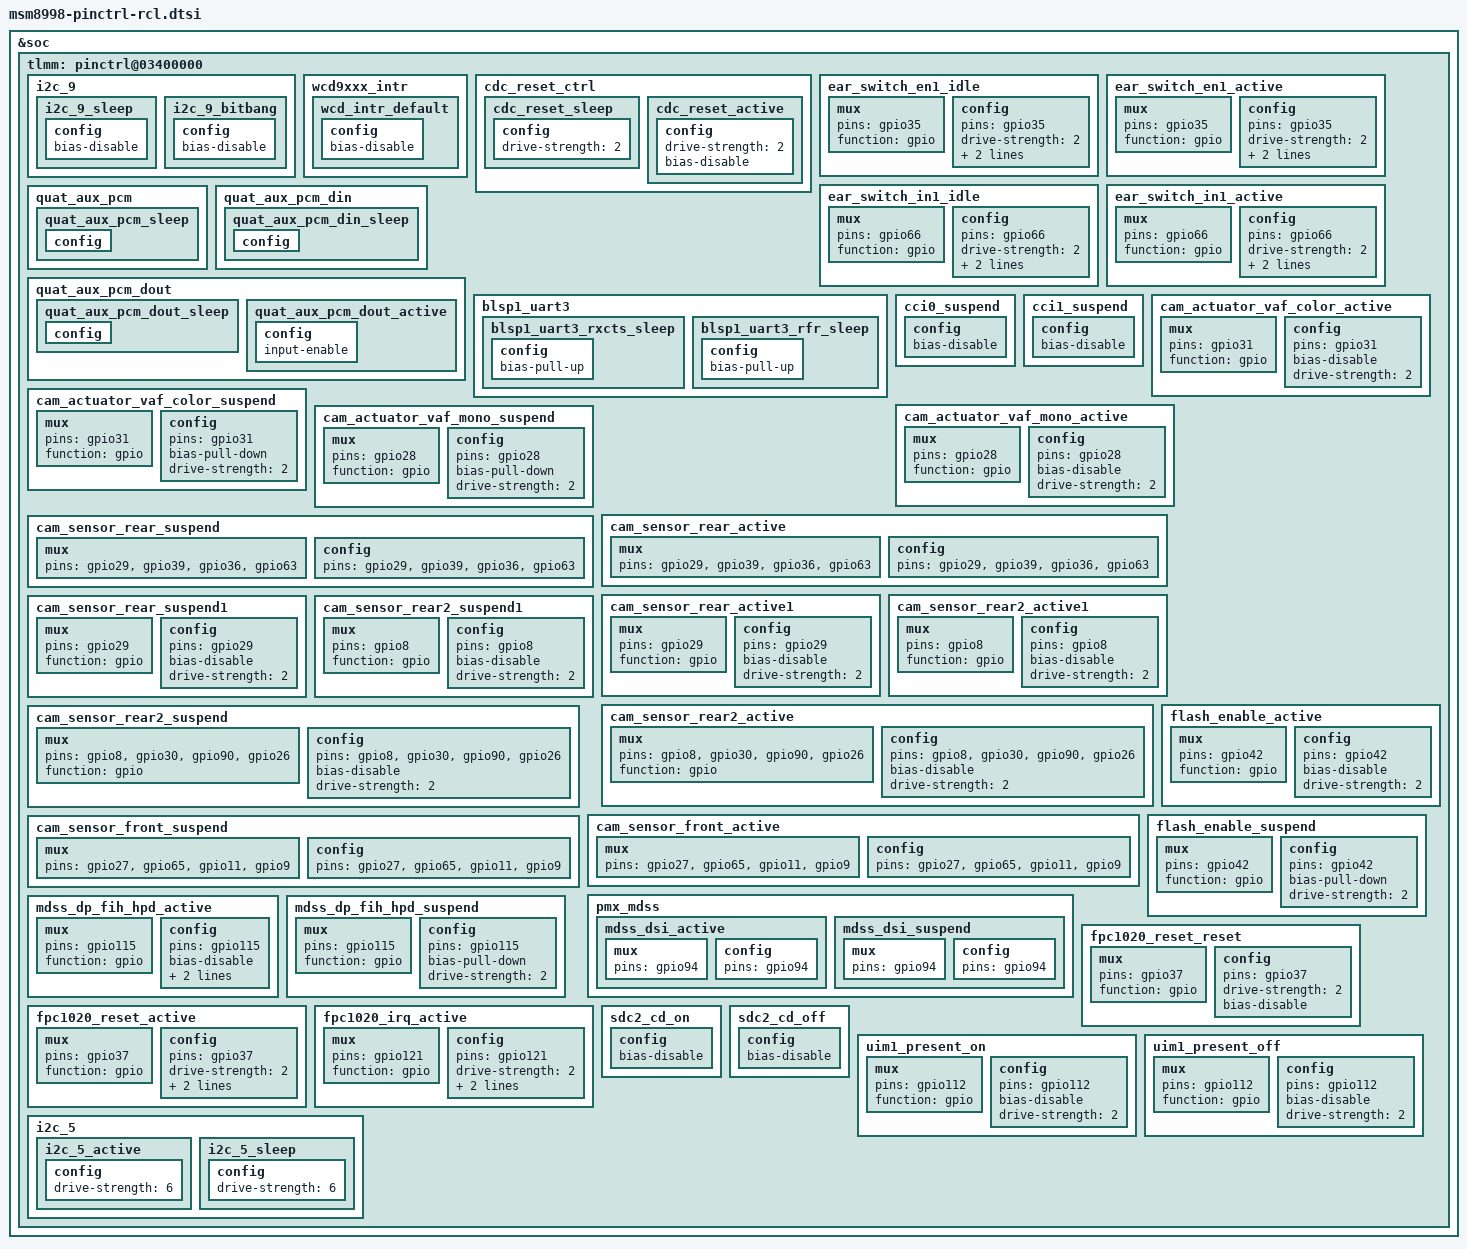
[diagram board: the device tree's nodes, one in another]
/* Copyright (c) 2015-2018, The Linux Foundation. All rights reserved.
 *
 * This program is free software; you can redistribute it and/or modify
 * it under the terms of the GNU General Public License version 2 and
 * only version 2 as published by the Free Software Foundation.
 *
 * This program is distributed in the hope that it will be useful,
 * but WITHOUT ANY WARRANTY; without even the implied warranty of
 * MERCHANTABILITY or FITNESS FOR A PARTICULAR PURPOSE.  See the
 * GNU General Public License for more details.
 */

&soc {
	tlmm: pinctrl@03400000 {
		/* Audio */
		i2c_9 {
			i2c_9_sleep: i2c_9_sleep {
				config {
					/delete-property/ bias-pull-up;
					bias-disable;
				};
			};

			i2c_9_bitbang: i2c_9_bitbang {
				config {
					/delete-property/ bias-pull-up;
					bias-disable;
				};
			};
		};

		wcd9xxx_intr {
			wcd_intr_default: wcd_intr_default {
				config {
					/delete-property/ bias-pull-down;
					bias-disable;
				};
			};
		};

		cdc_reset_ctrl {
			cdc_reset_sleep: cdc_reset_sleep {
				config {
					drive-strength = <2>;
				};
			};

			cdc_reset_active: cdc_reset_active {
				config {
					drive-strength = <2>;
					/delete-property/ bias-pull-down;
					bias-disable;
				};
			};
		};

		ear_switch_en1_idle: ear_switch_en1_idle {
			mux {
				pins = "gpio35";
				function = "gpio";
			};

			config {
				pins = "gpio35";
				drive-strength = <2>;
				bias-pull-down;
				output-low;
			};
		};

		ear_switch_en1_active: ear_switch_en1_active {
			mux {
				pins = "gpio35";
				function = "gpio";
			};

			config {
				pins = "gpio35";
				drive-strength = <2>;
				bias-disable;
				output-high;
			};
		};

		ear_switch_in1_idle: ear_switch_in1_idle {
			mux {
				pins = "gpio66";
				function = "gpio";
			};

			config {
				pins = "gpio66";
				drive-strength = <2>;
				bias-pull-down;
				output-low;
			};
		};

		ear_switch_in1_active: ear_switch_in1_active {
			mux {
				pins = "gpio66";
				function = "gpio";
			};

			config {
				pins = "gpio66";
				drive-strength = <2>;
				bias-disable;
				output-high;
			};
		};

		quat_aux_pcm {
			quat_aux_pcm_sleep: quat_aux_pcm_sleep {
				config {
					/delete-property/ input-enable;
				};
			};
		};

		quat_aux_pcm_din {
			quat_aux_pcm_din_sleep: quat_aux_pcm_din_sleep {
				config {
					/delete-property/ input-enable;
				};
			};
		};

		quat_aux_pcm_dout {
			quat_aux_pcm_dout_sleep: quat_aux_pcm_dout_sleep {
				config {
					/delete-property/ input-enable;
				};
			};

			quat_aux_pcm_dout_active: quat_aux_pcm_dout_active {
				config {
					input-enable;
				};
			};
		};

		/* Bluetooth */
		blsp1_uart3: blsp1_uart3 {
			blsp1_uart3_rxcts_sleep: blsp1_uart3_rxcts_sleep {
				config {
					/delete-property/ bias-no-pull;
					bias-pull-up;
				};
			};

			blsp1_uart3_rfr_sleep: blsp1_uart3_rfr_sleep {
				config {
					/delete-property/ bias-no-pull;
					bias-pull-up;
				};
			};
		};

		/* Camera */
		cci0_suspend: cci0_suspend {
			config {
				/delete-property/ bias-pull-down;
				bias-disable; /* No PULL */
			};
		};

		cci1_suspend: cci1_suspend {
			config {
				/delete-property/ bias-pull-down;
				bias-disable; /* No PULL */
			};
		};

		cam_actuator_vaf_color_active: cam_actuator_vaf_color_active {
			/* ACTUATOR POWER */
			mux {
				pins = "gpio31";
				function = "gpio";
			};

			config {
				pins = "gpio31";
				bias-disable; /* No PULL */
				drive-strength = <2>; /* 2 MA */
			};
		};

		cam_actuator_vaf_color_suspend: cam_actuator_vaf_color_suspend {
			/* ACTUATOR POWER */
			mux {
				pins = "gpio31";
				function = "gpio";
			};

			config {
				pins = "gpio31";
				bias-pull-down; /* PULL DOWN */
				drive-strength = <2>; /* 2 MA */
			};
		};

		cam_actuator_vaf_mono_active: cam_actuator_vaf_mono_active {
			/* ACTUATOR POWER */
			mux {
				pins = "gpio28";
				function = "gpio";
			};

			config {
				pins = "gpio28";
				bias-disable; /* No PULL */
				drive-strength = <2>; /* 2 MA */
			};
		};

		cam_actuator_vaf_mono_suspend: cam_actuator_vaf_mono_suspend {
			/* ACTUATOR POWER */
			mux {
				pins = "gpio28";
				function = "gpio";
			};

			config {
				pins = "gpio28";
				bias-pull-down; /* PULL DOWN */
				drive-strength = <2>; /* 2 MA */
			};
		};

		cam_sensor_rear_active: cam_sensor_rear_active {
			/* RESET, DVDD_EN, AVDD_EN, IOVDD_EN */
			mux {
				pins = "gpio29", "gpio39", "gpio36", "gpio63";
			};

			config {
				pins = "gpio29", "gpio39", "gpio36", "gpio63";
			};
		};

		cam_sensor_rear_suspend: cam_sensor_rear_suspend {
			/* RESET, DVDD_EN, AVDD_EN, IOVDD_EN */
			mux {
				pins = "gpio29", "gpio39", "gpio36", "gpio63";
			};

			config {
				pins = "gpio29", "gpio39", "gpio36", "gpio63";
			};
		};

		cam_sensor_rear_active1: cam_sensor_rear_active1 {
			mux {
				pins = "gpio29";
				function = "gpio";
			};

			config {
				pins = "gpio29";
				bias-disable; /* No PULL */
				drive-strength = <2>; /* 2 MA */
			};
		};

		cam_sensor_rear2_active1: cam_sensor_rear2_active1 {
			mux {
				pins = "gpio8";
				function = "gpio";
			};

			config {
				pins = "gpio8";
				bias-disable; /* No PULL */
				drive-strength = <2>; /* 2 MA */
			};
		};

		cam_sensor_rear_suspend1: cam_sensor_rear_suspend1 {
			mux {
				pins = "gpio29";
				function = "gpio";
			};

			config {
				pins = "gpio29";
				bias-disable; /* No PULL */
				drive-strength = <2>; /* 2 MA */
			};
		};

		cam_sensor_rear2_suspend1: cam_sensor_rear2_suspend1 {
			mux {
				pins = "gpio8";
				function = "gpio";
			};

			config {
				pins = "gpio8";
				bias-disable; /* No PULL */
				drive-strength = <2>; /* 2 MA */
			};
		};

		cam_sensor_rear2_active: cam_sensor_rear2_active {
			/* RESET, AVDD_EN, DVDD_EN, IOVDD_EN */
			mux {
				pins = "gpio8", "gpio30", "gpio90", "gpio26";
				function = "gpio";
			};

			config {
				pins = "gpio8", "gpio30", "gpio90", "gpio26";
				bias-disable; /* No PULL */
				drive-strength = <2>; /* 2 MA */
			};
		};

		cam_sensor_rear2_suspend: cam_sensor_rear2_suspend {
			/* RESET, AVDD_EN, DVDD_EN, IOVDD_EN */
			mux {
				pins = "gpio8", "gpio30", "gpio90", "gpio26";
				function = "gpio";
			};
			config {
				pins = "gpio8", "gpio30", "gpio90", "gpio26";
				bias-disable; /* No PULL */
				drive-strength = <2>; /* 2 MA */
			};
		};

		cam_sensor_front_active: cam_sensor_front_active {
			/* RESET, DVDD_EN, AVDD_EN, IOVDD_EN */
			mux {
				pins = "gpio27", "gpio65", "gpio11", "gpio9";
			};

			config {
				pins = "gpio27", "gpio65", "gpio11", "gpio9";
			};
		};

		cam_sensor_front_suspend: cam_sensor_front_suspend {
			/* RESET, DVDD_EN, AVDD_EN, IOVDD_EN */
			mux {
				pins = "gpio27", "gpio65", "gpio11", "gpio9";
			};

			config {
				pins = "gpio27", "gpio65", "gpio11", "gpio9";
			};
		};

		flash_enable_active: flash_enable_active {
			mux {
				pins = "gpio42";
				function = "gpio";
			};

			config {
				pins = "gpio42";
				bias-disable; /* No PULL */
				drive-strength = <2>; /* 2 MA */
			};
		};

		flash_enable_suspend: flash_enable_suspend {
			mux {
				pins = "gpio42";
				function = "gpio";
			};

			config {
				pins = "gpio42";
				bias-pull-down; /* PULL DOWN */
				drive-strength = <2>; /* 2 MA */
			};
		};

		/* Display */
		pmx_mdss: pmx_mdss {
			mdss_dsi_active: mdss_dsi_active {
				mux {
					pins = "gpio94";
				};

				config {
					pins = "gpio94";
				};
			};

			mdss_dsi_suspend: mdss_dsi_suspend {
				mux {
					pins = "gpio94";
				};

				config {
					pins = "gpio94";
				};
			};
		};

		mdss_dp_fih_hpd_active: mdss_dp_fih_hpd_active {
			mux {
				pins = "gpio115";
				function = "gpio";
			};

			config {
				pins = "gpio115";
				bias-disable;
				drive-strength = <16>;
				output-low;
			};
		};

		mdss_dp_fih_hpd_suspend: mdss_dp_fih_hpd_suspend {
			mux {
				pins = "gpio115";
				function = "gpio";
			};

			config {
				pins = "gpio115";
				bias-pull-down;
				drive-strength = <2>;
			};
		};

		/* Fingerprint */
		fpc1020_reset_reset: fpc1020_reset_reset {
			mux {
				pins = "gpio37";
				function = "gpio";
			};

			config {
				pins = "gpio37";
				drive-strength = <2>;
				bias-disable;
			};
		};

		fpc1020_reset_active: fpc1020_reset_active {
			mux {
				pins = "gpio37";
				function = "gpio";
			};

			config {
				pins = "gpio37";
				drive-strength = <2>;
				bias-disable;
				output-high;
			};
		};

		fpc1020_irq_active: fpc1020_irq_active {
			mux {
				pins = "gpio121";
				function = "gpio";
			};

			config {
				pins = "gpio121";
				drive-strength = <2>;
				bias-disable;
				input-enable;
			};
		};

		/* SD */
		sdc2_cd_on: sdc2_cd_on {
			config {
				/delete-property/ bias-pull-up;
				bias-disable;           /* no pull */
			};
		};

		sdc2_cd_off: sdc2_cd_off {
			config {
				/delete-property/ bias-pull-up;
				bias-disable;           /* no pull */
			};
		};

		/* SIM */
		uim1_present_on: uim1_present_on {
			mux {
				pins = "gpio112";
				function = "gpio";
			};

			config {
				pins = "gpio112";
				bias-disable;           /* no pull */
				drive-strength = <2>;   /* 2 MA */
			};
		};

		uim1_present_off: uim1_present_off {
			mux {
				pins = "gpio112";
				function = "gpio";
			};

			config {
				pins = "gpio112";
				bias-disable;           /* no pull */
				drive-strength = <2>;   /* 2 MA */
			};
		};

		/* Touchscreen */
		i2c_5 {
			i2c_5_active: i2c_5_active {
				config {
					drive-strength = <6>;
				};
			};

			i2c_5_sleep: i2c_5_sleep {
				config {
					drive-strength = <6>;
				};
			};
		};
	};
};
